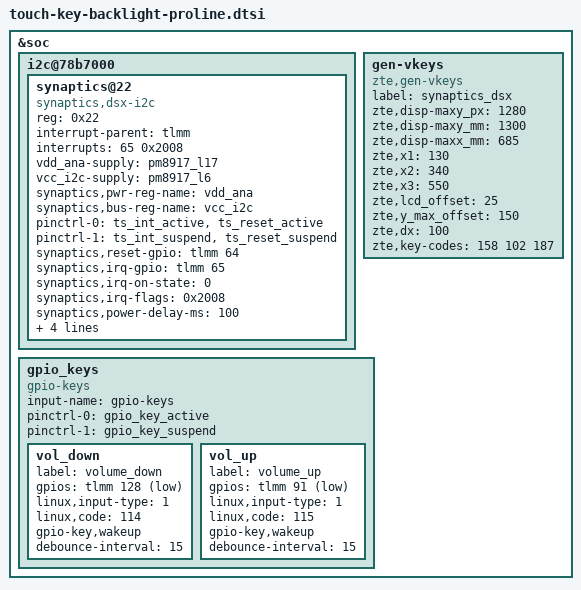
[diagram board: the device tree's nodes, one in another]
//for touchscreen and key and keypad-backlight

&soc {
	i2c@78b7000 { /* BLSP3 QUP5 */
		synaptics@22 {
			compatible = "synaptics,dsx-i2c";
			reg = <0x22>;
			interrupt-parent = <&tlmm>;
			interrupts = <65 0x2008>;
			vdd_ana-supply = <&pm8917_l17>;
			vcc_i2c-supply = <&pm8917_l6>;
			synaptics,pwr-reg-name = "vdd_ana";
			synaptics,bus-reg-name = "vcc_i2c";
			/* pins used by touchscreen */
			pinctrl-names = "pmx_ts_active","pmx_ts_suspend";
			pinctrl-0 = <&ts_int_active &ts_reset_active>;
			pinctrl-1 = <&ts_int_suspend &ts_reset_suspend>;
			synaptics,reset-gpio = <&tlmm 64 0x0>;
			synaptics,irq-gpio = <&tlmm 65 0x0>;
			synaptics,irq-on-state = <0>;
			synaptics,irq-flags = <0x2008>; /* IRQF_ONESHOT | IRQF_TRIGGER_LOW */
			synaptics,power-delay-ms = <100>;
			synaptics,reset-delay-ms = <100>;
			synaptics,reset-on-state = <0>;
			synaptics,reset-active-ms = <20>;
			synaptics,cap-button-codes = <158 102 187>;


		};

	};

	gen-vkeys {
		compatible = "zte,gen-vkeys";
		label = "synaptics_dsx";
		zte,disp-maxy_px = <1280>;
		zte,disp-maxy_mm = <1300>;//0.1mm
		zte,disp-maxx_mm = <685>;//0.1mm
		zte,x1=<130>;
		zte,x2=<340>;
		zte,x3=<550>;
		zte,lcd_offset=<25>;//?àà?LCD?áéù2mm ?aà??ù·??í0.5mm
		zte,y_max_offset=<150>;//??è??μLCD??±???μ?°′?ü??±????àà?1à??è?′ó?μ×?óàá?
		zte,dx=<100>;//±ê×??DX·??§?a5mm+-1mmè??D?μ*2
		zte,key-codes = <158 102 187>;
	};


	gpio_keys {
		compatible = "gpio-keys";
		input-name = "gpio-keys";
		pinctrl-names = "tlmm_gpio_key_active","tlmm_gpio_key_suspend";
		pinctrl-0 = <&gpio_key_active>;
		pinctrl-1 = <&gpio_key_suspend>;

		vol_down {
			label = "volume_down";
			gpios = <&tlmm 128 0x1>;
			linux,input-type = <1>;
			linux,code = <114>;
			gpio-key,wakeup;
			debounce-interval = <15>;
		};
		vol_up {
			label = "volume_up";
			gpios = <&tlmm 91 0x1>;
			linux,input-type = <1>;
			linux,code = <115>;
			gpio-key,wakeup;
			debounce-interval = <15>;
		};
	};
};



